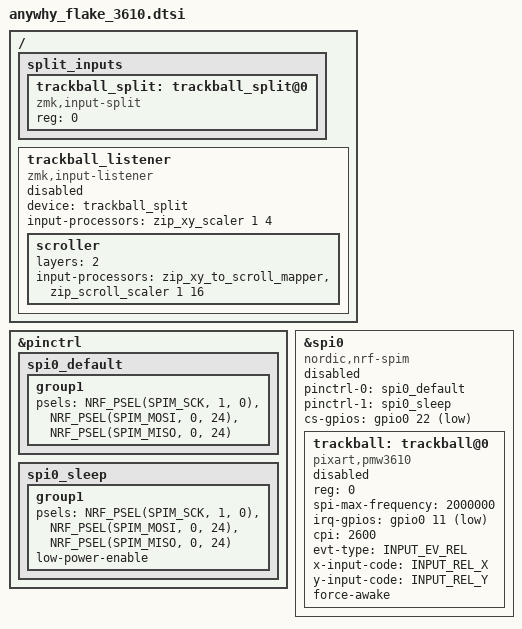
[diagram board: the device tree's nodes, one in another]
#include <zephyr/dt-bindings/input/input-event-codes.h>

#define INPUT_EV_KEY 0x01               /**< Key event */
#define INPUT_EV_REL 0x02               /**< Relative coordinate event */
#define INPUT_EV_ABS 0x03               /**< Absolute coordinate event */
#define INPUT_EV_MSC 0x04               /**< Miscellaneous event */
#define INPUT_EV_VENDOR_START 0xf0      /**< Vendor specific event start */
#define INPUT_EV_VENDOR_STOP 0xff       /**< Vendor specific event stop */

#define INPUT_REL_X 0x00                /**< Relative X coordinate */
#define INPUT_REL_Y 0x01                /**< Relative Y coordinate */
#define INPUT_REL_WHEEL 0x08            /**< Relative wheel coordinate */
#define INPUT_REL_HWHEEL 0x06           /**< Relative horizontal wheel coordinate */
#define INPUT_REL_MISC 0x09             /**< Relative misc coordinate */

&pinctrl {
    spi0_default: spi0_default {
        group1 {
            psels = <NRF_PSEL(SPIM_SCK, 1, 0)>,
                <NRF_PSEL(SPIM_MOSI, 0, 24)>,
                <NRF_PSEL(SPIM_MISO, 0, 24)>;
        };
    };

    spi0_sleep: spi0_sleep {
        group1 {
            psels = <NRF_PSEL(SPIM_SCK, 1, 0)>,
                <NRF_PSEL(SPIM_MOSI, 0, 24)>,
                <NRF_PSEL(SPIM_MISO, 0, 24)>;
            low-power-enable;
        };
    };
};

&spi0 {
    status = "disabled";
    compatible = "nordic,nrf-spim";
    pinctrl-0 = <&spi0_default>;
    pinctrl-1 = <&spi0_sleep>;
    pinctrl-names = "default", "sleep";
    cs-gpios = <&gpio0 22 GPIO_ACTIVE_LOW>;

    trackball: trackball@0 {
        status = "disabled";
        compatible = "pixart,pmw3610";
        reg = <0>;
        spi-max-frequency = <2000000>;
        irq-gpios = <&gpio0 11 (GPIO_ACTIVE_LOW | GPIO_PULL_UP)>;
        cpi = <2600>;
        evt-type = <INPUT_EV_REL>;
        x-input-code = <INPUT_REL_X>;
        y-input-code = <INPUT_REL_Y>;

        force-awake;
        /* keep the sensor awake while ZMK activity state is ACTIVE,
           fallback to normal downshift mode after ZMK goes into IDLE / SLEEP mode.
           thus, the sensor would be a `wakeup-source` */
    };
};

/ {
    split_inputs {
        #address-cells = <1>;
        #size-cells = <0>;

        trackball_split: trackball_split@0 {
            compatible = "zmk,input-split";
            reg = <0>;
        };
    };

    trackball_listener: trackball_listener {
        compatible = "zmk,input-listener";
        status = "disabled"; // overridden on central
        device = <&trackball_split>;
         /* base processor chain on all layers */
        input-processors = <
            &zip_xy_scaler 1 4 
        >;

        scroller: scroller {
            layers           = <2>;
            input-processors = <
                &zip_xy_to_scroll_mapper                         // Converts XY movement to scroll events
                &zip_scroll_scaler 1 16                           // Scales the scroll speed (e.g., 1/6 speed)
            >;
        };
    };
};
